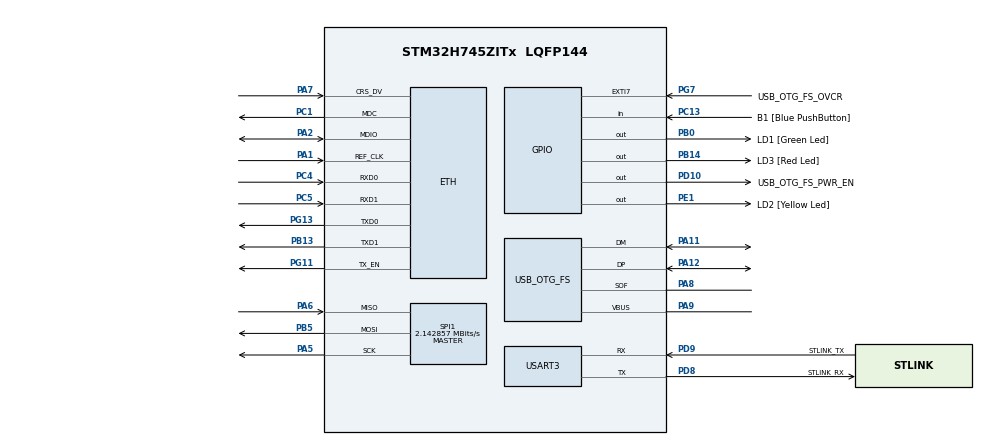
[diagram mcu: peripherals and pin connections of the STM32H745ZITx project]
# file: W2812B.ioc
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CORTEX_M7.CPU_DCache=Disabled
CORTEX_M7.CPU_ICache=Enabled
CortexM4.IPs=FATFS_M4\:I,FREERTOS_M4\:I,IWDG2\:I,RCC,WWDG2\:I,DMA,BDMA,MDMA,NVIC2\:I,USART3,ETH,DEBUG,USB_DEVICE_M4\:I,USB_HOST_M4\:I,PDM2PCM_M4\:I,PWR,RESMGR_UTILITY,SYS_M4\:I,CORTEX_M4\:I,OPENAMP_M4\:I,VREFBUF
CortexM7.IPs=FATFS_M7\:I,FREERTOS_M7\:I,IWDG1\:I,RCC\:I,WWDG1\:I,DMA\:I,BDMA\:I,MDMA\:I,NVIC1\:I,SYS\:I,USART3\:I,USB_OTG_FS\:I,ETH\:I,CORTEX_M7\:I,DEBUG\:I,USB_DEVICE_M7\:I,USB_HOST_M7\:I,PDM2PCM_M7\:I,PWR\:I,RESMGR_UTILITY\:I,OPENAMP_M7\:I,VREFBUF\:I,SPI1\:I
Dma.Request0=SPI1_TX
Dma.SPI1_TX.0.Direction=DMA_MEMORY_TO_PERIPH
Dma.SPI1_TX.0.EventEnable=DISABLE
Dma.SPI1_TX.0.FIFOMode=DMA_FIFOMODE_DISABLE
Dma.SPI1_TX.0.Instance=DMA2_Stream0
Dma.SPI1_TX.0.MemDataAlignment=DMA_MDATAALIGN_BYTE
Dma.SPI1_TX.0.MemInc=DMA_MINC_ENABLE
Dma.SPI1_TX.0.Mode=DMA_CIRCULAR
Dma.SPI1_TX.0.PeriphDataAlignment=DMA_PDATAALIGN_BYTE
Dma.SPI1_TX.0.PeriphInc=DMA_PINC_DISABLE
Dma.SPI1_TX.0.Polarity=HAL_DMAMUX_REQ_GEN_RISING
Dma.SPI1_TX.0.Priority=DMA_PRIORITY_LOW
Dma.SPI1_TX.0.RequestNumber=1
Dma.SPI1_TX.0.SignalID=NONE
Dma.SPI1_TX.0.SyncEnable=DISABLE
Dma.SPI1_TX.0.SyncPolarity=HAL_DMAMUX_SYNC_NO_EVENT
Dma.SPI1_TX.0.SyncRequestNumber=1
Dma.SPI1_TX.0.SyncSignalID=NONE
ETH.MediaInterface=HAL_ETH_RMII_MODE
Mcu.Family=STM32H7
Mcu.Name=STM32H745ZITx
Mcu.Package=LQFP144
NVIC1.DMA2_Stream0_IRQn=true\:0\:0\:false\:false\:true\:false\:true
NVIC1.PriorityGroup=NVIC_PRIORITYGROUP_4
NVIC1.SPI1_IRQn=true\:0\:0\:false\:false\:true\:false\:true
NVIC2.PriorityGroup=NVIC_PRIORITYGROUP_4
PA1.Mode=RMII
PA1.PinAttribute=CortexM7
PA1.Signal=ETH_REF_CLK
PA11.Mode=Device_Only
PA11.PinAttribute=CortexM7
PA11.Signal=USB_OTG_FS_DM
PA12.Mode=Device_Only
PA12.PinAttribute=CortexM7
PA12.Signal=USB_OTG_FS_DP
PA2.Mode=RMII
PA2.PinAttribute=CortexM7
PA2.Signal=ETH_MDIO
PA5.GPIO_Speed=GPIO_SPEED_FREQ_LOW
PA5.Mode=Full_Duplex_Master
PA5.PinAttribute=CortexM7
PA5.Signal=SPI1_SCK
PA6.Mode=Full_Duplex_Master
PA6.PinAttribute=CortexM7
PA6.Signal=SPI1_MISO
PA7.Mode=RMII
PA7.PinAttribute=CortexM7
PA7.Signal=ETH_CRS_DV
PA8.Mode=Activate_SOF_FS
PA8.PinAttribute=CortexM7
PA8.Signal=USB_OTG_FS_SOF
PA9.Mode=Activate_VBUS
PA9.PinAttribute=CortexM7
PA9.Signal=USB_OTG_FS_VBUS
PB0.GPIO_Label=LD1 [Green Led]
PB0.PinAttribute=Free
PB0.Signal=GPIO_Output
PB13.Mode=RMII
PB13.PinAttribute=CortexM7
PB13.Signal=ETH_TXD1
PB14.GPIO_Label=LD3 [Red Led]
PB14.PinAttribute=Free
PB14.Signal=GPIO_Output
PB5.GPIO_Speed=GPIO_SPEED_FREQ_VERY_HIGH
PB5.Mode=Full_Duplex_Master
PB5.PinAttribute=CortexM7
PB5.Signal=SPI1_MOSI
PC1.Mode=RMII
PC1.PinAttribute=CortexM7
PC1.Signal=ETH_MDC
PC13.GPIO_Label=B1 [Blue PushButton]
PC13.PinAttribute=Free
PC13.Signal=GPIO_Input
PC14-OSC32_IN\ (OSC32_IN).Mode=LSE-External-Oscillator
PC14-OSC32_IN\ (OSC32_IN).PinAttribute=CortexM7
PC14-OSC32_IN\ (OSC32_IN).Signal=RCC_OSC32_IN
PC15-OSC32_OUT\ (OSC32_OUT).Mode=LSE-External-Oscillator
PC15-OSC32_OUT\ (OSC32_OUT).PinAttribute=CortexM7
PC15-OSC32_OUT\ (OSC32_OUT).Signal=RCC_OSC32_OUT
PC4.Mode=RMII
PC4.PinAttribute=CortexM7
PC4.Signal=ETH_RXD0
PC5.Mode=RMII
PC5.PinAttribute=CortexM7
PC5.Signal=ETH_RXD1
PD10.GPIO_Label=USB_OTG_FS_PWR_EN
PD10.PinAttribute=Free
PD10.Signal=GPIO_Output
PD8.GPIO_Label=STLINK_RX
PD8.Mode=Asynchronous
PD8.PinAttribute=CortexM7
PD8.Signal=USART3_TX
PD9.GPIO_Label=STLINK_TX
PD9.Mode=Asynchronous
PD9.PinAttribute=CortexM7
PD9.Signal=USART3_RX
PE1.GPIO_Label=LD2 [Yellow Led]
PE1.PinAttribute=Free
PE1.Signal=GPIO_Output
PG11.Mode=RMII
PG11.PinAttribute=CortexM7
PG11.Signal=ETH_TX_EN
PG13.Mode=RMII
PG13.PinAttribute=CortexM7
PG13.Signal=ETH_TXD0
PG7.GPIO_Label=USB_OTG_FS_OVCR
PG7.PinAttribute=Free
PG7.Signal=GPXTI7
PH0-OSC_IN\ (PH0).Mode=HSE-External-Clock-Source
PH0-OSC_IN\ (PH0).PinAttribute=CortexM7
PH0-OSC_IN\ (PH0).Signal=RCC_OSC_IN
PH1-OSC_OUT\ (PH1).PinAttribute=CortexM7
PH1-OSC_OUT\ (PH1).Signal=RCC_OSC_OUT
ProjectManager.HeapSize=M4-0x200,M7-0x200
ProjectManager.StackSize=M4-0x400,M7-0x400
ProjectManager.TargetToolchain=STM32CubeIDE
RCC.ADCFreq_Value=16125000
RCC.APB1Freq_Value=120000000
RCC.APB2Freq_Value=120000000
RCC.APB3Freq_Value=120000000
RCC.APB4Freq_Value=120000000
RCC.CortexFreq_Value=480000000
RCC.D1PPRE=RCC_APB3_DIV2
RCC.D2PPRE1=RCC_APB1_DIV2
RCC.D2PPRE2=RCC_APB2_DIV2
RCC.D3PPRE=RCC_APB4_DIV2
RCC.DIVM1=1
RCC.DIVM3=1
RCC.DIVN1=120
RCC.DIVN3=24
RCC.DIVQ1=7
RCC.DIVQ3=4
RCC.HCLKFreq_Value=240000000
RCC.HPRE=RCC_HCLK_DIV2
RCC.HSE_VALUE=8000000
RCC.PLL2FRACN=0
RCC.PLL3FRACN=0
RCC.PLLFRACN=0
RCC.SYSCLKFreq_VALUE=480000000
RCC.SYSCLKSource=RCC_SYSCLKSOURCE_PLLCLK
RCC.SupplySource=PWR_DIRECT_SMPS_SUPPLY
RCC.USBCLockSelection=RCC_USBCLKSOURCE_PLL3
RCC.USBFreq_Value=48000000
SPI1.BaudRatePrescaler=SPI_BAUDRATEPRESCALER_64
SPI1.CalculateBaudRate=2.142857 MBits/s
SPI1.DataSize=SPI_DATASIZE_8BIT
SPI1.Direction=SPI_DIRECTION_2LINES
SPI1.MasterKeepIOState=SPI_MASTER_KEEP_IO_STATE_ENABLE
SPI1.Mode=SPI_MODE_MASTER
SPI1.NSSPMode=SPI_NSS_PULSE_DISABLE
SPI1.VirtualType=VM_MASTER
USART3.VirtualMode-Asynchronous=VM_ASYNC
USB_OTG_FS.VirtualMode=Device_Only
VP_SYS_M4_VS_Systick.Mode=SysTick
board=NUCLEO-H745ZI-Q

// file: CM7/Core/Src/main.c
/* USER CODE BEGIN Header */
/**
  ******************************************************************************
  * @file           : main.c
  * @brief          : Main program body
  ******************************************************************************
  * @attention
  *
  * <h2><center>&copy; Copyright (c) 2021 STMicroelectronics.
  * All rights reserved.</center></h2>
  *
  * This software component is licensed by ST under BSD 3-Clause license,
  * the "License"; You may not use this file except in compliance with the
  * License. You may obtain a copy of the License at:
  *                        opensource.org/licenses/BSD-3-Clause
  *
  ******************************************************************************
  */
/* USER CODE END Header */
#include "main.h"
#include "string.h"

/* USER CODE BEGIN Includes */
#include "W2812BSPI.h"
/* USER CODE END Includes */

/* USER CODE BEGIN PD */

#ifndef HSEM_ID_0
#define HSEM_ID_0 (0U) /* HW semaphore 0*/
#endif
/* USER CODE END PD */

#if defined ( __ICCARM__ ) /*!< IAR Compiler */

#pragma location=0x30040000
ETH_DMADescTypeDef  DMARxDscrTab[ETH_RX_DESC_CNT]; /* Ethernet Rx DMA Descriptors */
#pragma location=0x30040060
ETH_DMADescTypeDef  DMATxDscrTab[ETH_TX_DESC_CNT]; /* Ethernet Tx DMA Descriptors */
#pragma location=0x30040200
uint8_t Rx_Buff[ETH_RX_DESC_CNT][ETH_MAX_PACKET_SIZE]; /* Ethernet Receive Buffers */

#elif defined ( __CC_ARM )  /* MDK ARM Compiler */

__attribute__((at(0x30040000))) ETH_DMADescTypeDef  DMARxDscrTab[ETH_RX_DESC_CNT]; /* Ethernet Rx DMA Descriptors */
__attribute__((at(0x30040060))) ETH_DMADescTypeDef  DMATxDscrTab[ETH_TX_DESC_CNT]; /* Ethernet Tx DMA Descriptors */
__attribute__((at(0x30040200))) uint8_t Rx_Buff[ETH_RX_DESC_CNT][ETH_MAX_PACKET_SIZE]; /* Ethernet Receive Buffer */

#elif defined ( __GNUC__ ) /* GNU Compiler */

ETH_DMADescTypeDef DMARxDscrTab[ETH_RX_DESC_CNT] __attribute__((section(".RxDecripSection"))); /* Ethernet Rx DMA Descriptors */
ETH_DMADescTypeDef DMATxDscrTab[ETH_TX_DESC_CNT] __attribute__((section(".TxDecripSection")));   /* Ethernet Tx DMA Descriptors */
uint8_t Rx_Buff[ETH_RX_DESC_CNT][ETH_MAX_PACKET_SIZE] __attribute__((section(".RxArraySection"))); /* Ethernet Receive Buffers */

#endif

ETH_TxPacketConfig TxConfig;

ETH_HandleTypeDef heth;

SPI_HandleTypeDef hspi1;
DMA_HandleTypeDef hdma_spi1_tx;

UART_HandleTypeDef huart3;

PCD_HandleTypeDef hpcd_USB_OTG_FS;

/* USER CODE BEGIN PV */
W2812BStructure LED[8]={0};

/* USER CODE END PV */

void SystemClock_Config(void);
static void MX_GPIO_Init(void);
static void MX_ETH_Init(void);
static void MX_USART3_UART_Init(void);
static void MX_USB_OTG_FS_PCD_Init(void);
static void MX_DMA_Init(void);
static void MX_SPI1_Init(void);

int main(void)
{
/* USER CODE BEGIN Boot_Mode_Sequence_0 */
  int32_t timeout;
/* USER CODE END Boot_Mode_Sequence_0 */

  /* Enable I-Cache---------------------------------------------------------*/
  SCB_EnableICache();

/* USER CODE BEGIN Boot_Mode_Sequence_1 */
  /* Wait until CPU2 boots and enters in stop mode or timeout*/
  timeout = 0xFFFF;
  while((__HAL_RCC_GET_FLAG(RCC_FLAG_D2CKRDY) != RESET) && (timeout-- > 0));
  if ( timeout < 0 )
  {
  Error_Handler();
  }
/* USER CODE END Boot_Mode_Sequence_1 */
  /* MCU Configuration--------------------------------------------------------*/

  /* Reset of all peripherals, Initializes the Flash interface and the Systick. */
  HAL_Init();

  /* Configure the system clock */
  SystemClock_Config();
/* USER CODE BEGIN Boot_Mode_Sequence_2 */
/* When system initialization is finished, Cortex-M7 will release Cortex-M4 by means of
HSEM notification */
/*HW semaphore Clock enable*/
__HAL_RCC_HSEM_CLK_ENABLE();
/*Take HSEM */
HAL_HSEM_FastTake(HSEM_ID_0);
/*Release HSEM in order to notify the CPU2(CM4)*/
HAL_HSEM_Release(HSEM_ID_0,0);
/* wait until CPU2 wakes up from stop mode */
timeout = 0xFFFF;
while((__HAL_RCC_GET_FLAG(RCC_FLAG_D2CKRDY) == RESET) && (timeout-- > 0));
if ( timeout < 0 )
{
Error_Handler();
}
/* USER CODE END Boot_Mode_Sequence_2 */

  /* Initialize all configured peripherals */
  MX_GPIO_Init();
  MX_ETH_Init();
  MX_USART3_UART_Init();
  MX_USB_OTG_FS_PCD_Init();
  MX_DMA_Init();
  MX_SPI1_Init();
  /* USER CODE BEGIN 2 */
  GPIOB->OTYPER = GPIOB->OTYPER | GPIO_PIN_5; // set output  open drain
  W2812B_Init(&hspi1);
  /* USER CODE END 2 */

  /* Infinite loop */
  /* USER CODE BEGIN WHILE */
  while (1)
  {
	  static int h =0;
    /* USER CODE END WHILE */

    /* USER CODE BEGIN 3 */

		HAL_Delay(1);
		for (int i = 0; i < 8; i++) {

			HToRGB((h + 192*i) % 1536, &LED[i]);
		}

		h++;
		h%=1536;
	  W2812B_UpdateData(LED);

  }
  /* USER CODE END 3 */
}

void SystemClock_Config(void)
{
  RCC_OscInitTypeDef RCC_OscInitStruct = {0};
  RCC_ClkInitTypeDef RCC_ClkInitStruct = {0};

  /** Supply configuration update enable
  */
  HAL_PWREx_ConfigSupply(PWR_DIRECT_SMPS_SUPPLY);
  /** Configure the main internal regulator output voltage
  */
  __HAL_PWR_VOLTAGESCALING_CONFIG(PWR_REGULATOR_VOLTAGE_SCALE0);

  while(!__HAL_PWR_GET_FLAG(PWR_FLAG_VOSRDY)) {}
  /** Macro to configure the PLL clock source
  */
  __HAL_RCC_PLL_PLLSOURCE_CONFIG(RCC_PLLSOURCE_HSE);
  /** Initializes the RCC Oscillators according to the specified parameters
  * in the RCC_OscInitTypeDef structure.
  */
  RCC_OscInitStruct.OscillatorType = RCC_OSCILLATORTYPE_HSE;
  RCC_OscInitStruct.HSEState = RCC_HSE_BYPASS;
  RCC_OscInitStruct.PLL.PLLState = RCC_PLL_ON;
  RCC_OscInitStruct.PLL.PLLSource = RCC_PLLSOURCE_HSE;
  RCC_OscInitStruct.PLL.PLLM = 1;
  RCC_OscInitStruct.PLL.PLLN = 120;
  RCC_OscInitStruct.PLL.PLLP = 2;
  RCC_OscInitStruct.PLL.PLLQ = 7;
  RCC_OscInitStruct.PLL.PLLR = 2;
  RCC_OscInitStruct.PLL.PLLRGE = RCC_PLL1VCIRANGE_3;
  RCC_OscInitStruct.PLL.PLLVCOSEL = RCC_PLL1VCOWIDE;
  RCC_OscInitStruct.PLL.PLLFRACN = 0;
  if (HAL_RCC_OscConfig(&RCC_OscInitStruct) != HAL_OK)
  {
    Error_Handler();
  }
  /** Initializes the CPU, AHB and APB buses clocks
  */
  RCC_ClkInitStruct.ClockType = RCC_CLOCKTYPE_HCLK|RCC_CLOCKTYPE_SYSCLK
                              |RCC_CLOCKTYPE_PCLK1|RCC_CLOCKTYPE_PCLK2
                              |RCC_CLOCKTYPE_D3PCLK1|RCC_CLOCKTYPE_D1PCLK1;
  RCC_ClkInitStruct.SYSCLKSource = RCC_SYSCLKSOURCE_PLLCLK;
  RCC_ClkInitStruct.SYSCLKDivider = RCC_SYSCLK_DIV1;
  RCC_ClkInitStruct.AHBCLKDivider = RCC_HCLK_DIV2;
  RCC_ClkInitStruct.APB3CLKDivider = RCC_APB3_DIV2;
  RCC_ClkInitStruct.APB1CLKDivider = RCC_APB1_DIV2;
  RCC_ClkInitStruct.APB2CLKDivider = RCC_APB2_DIV2;
  RCC_ClkInitStruct.APB4CLKDivider = RCC_APB4_DIV2;

  if (HAL_RCC_ClockConfig(&RCC_ClkInitStruct, FLASH_LATENCY_4) != HAL_OK)
  {
    Error_Handler();
  }
}

static void MX_ETH_Init(void)
{

   static uint8_t MACAddr[6];

  heth.Instance = ETH;
  MACAddr[0] = 0x00;
  MACAddr[1] = 0x80;
  MACAddr[2] = 0xE1;
  MACAddr[3] = 0x00;
  MACAddr[4] = 0x00;
  MACAddr[5] = 0x00;
  heth.Init.MACAddr = &MACAddr[0];
  heth.Init.MediaInterface = HAL_ETH_RMII_MODE;
  heth.Init.TxDesc = DMATxDscrTab;
  heth.Init.RxDesc = DMARxDscrTab;
  heth.Init.RxBuffLen = 1524;

  if (HAL_ETH_Init(&heth) != HAL_OK)
  {
    Error_Handler();
  }

  memset(&TxConfig, 0 , sizeof(ETH_TxPacketConfig));
  TxConfig.Attributes = ETH_TX_PACKETS_FEATURES_CSUM | ETH_TX_PACKETS_FEATURES_CRCPAD;
  TxConfig.ChecksumCtrl = ETH_CHECKSUM_IPHDR_PAYLOAD_INSERT_PHDR_CALC;
  TxConfig.CRCPadCtrl = ETH_CRC_PAD_INSERT;

}

static void MX_SPI1_Init(void)
{

  /* SPI1 parameter configuration*/
  hspi1.Instance = SPI1;
  hspi1.Init.Mode = SPI_MODE_MASTER;
  hspi1.Init.Direction = SPI_DIRECTION_2LINES;
  hspi1.Init.DataSize = SPI_DATASIZE_8BIT;
  hspi1.Init.CLKPolarity = SPI_POLARITY_LOW;
  hspi1.Init.CLKPhase = SPI_PHASE_1EDGE;
  hspi1.Init.NSS = SPI_NSS_SOFT;
  hspi1.Init.BaudRatePrescaler = SPI_BAUDRATEPRESCALER_64;
  hspi1.Init.FirstBit = SPI_FIRSTBIT_MSB;
  hspi1.Init.TIMode = SPI_TIMODE_DISABLE;
  hspi1.Init.CRCCalculation = SPI_CRCCALCULATION_DISABLE;
  hspi1.Init.CRCPolynomial = 0x0;
  hspi1.Init.NSSPMode = SPI_NSS_PULSE_DISABLE;
  hspi1.Init.NSSPolarity = SPI_NSS_POLARITY_LOW;
  hspi1.Init.FifoThreshold = SPI_FIFO_THRESHOLD_01DATA;
  hspi1.Init.TxCRCInitializationPattern = SPI_CRC_INITIALIZATION_ALL_ZERO_PATTERN;
  hspi1.Init.RxCRCInitializationPattern = SPI_CRC_INITIALIZATION_ALL_ZERO_PATTERN;
  hspi1.Init.MasterSSIdleness = SPI_MASTER_SS_IDLENESS_00CYCLE;
  hspi1.Init.MasterInterDataIdleness = SPI_MASTER_INTERDATA_IDLENESS_00CYCLE;
  hspi1.Init.MasterReceiverAutoSusp = SPI_MASTER_RX_AUTOSUSP_DISABLE;
  hspi1.Init.MasterKeepIOState = SPI_MASTER_KEEP_IO_STATE_ENABLE;
  hspi1.Init.IOSwap = SPI_IO_SWAP_DISABLE;
  if (HAL_SPI_Init(&hspi1) != HAL_OK)
  {
    Error_Handler();
  }

}

static void MX_USART3_UART_Init(void)
{

  huart3.Instance = USART3;
  huart3.Init.BaudRate = 115200;
  huart3.Init.WordLength = UART_WORDLENGTH_8B;
  huart3.Init.StopBits = UART_STOPBITS_1;
  huart3.Init.Parity = UART_PARITY_NONE;
  huart3.Init.Mode = UART_MODE_TX_RX;
  huart3.Init.HwFlowCtl = UART_HWCONTROL_NONE;
  huart3.Init.OverSampling = UART_OVERSAMPLING_16;
  huart3.Init.OneBitSampling = UART_ONE_BIT_SAMPLE_DISABLE;
  huart3.Init.ClockPrescaler = UART_PRESCALER_DIV1;
  huart3.AdvancedInit.AdvFeatureInit = UART_ADVFEATURE_NO_INIT;
  if (HAL_UART_Init(&huart3) != HAL_OK)
  {
    Error_Handler();
  }
  if (HAL_UARTEx_SetTxFifoThreshold(&huart3, UART_TXFIFO_THRESHOLD_1_8) != HAL_OK)
  {
    Error_Handler();
  }
  if (HAL_UARTEx_SetRxFifoThreshold(&huart3, UART_RXFIFO_THRESHOLD_1_8) != HAL_OK)
  {
    Error_Handler();
  }
  if (HAL_UARTEx_DisableFifoMode(&huart3) != HAL_OK)
  {
    Error_Handler();
  }

}

static void MX_USB_OTG_FS_PCD_Init(void)
{

  hpcd_USB_OTG_FS.Instance = USB_OTG_FS;
  hpcd_USB_OTG_FS.Init.dev_endpoints = 9;
  hpcd_USB_OTG_FS.Init.speed = PCD_SPEED_FULL;
  hpcd_USB_OTG_FS.Init.dma_enable = DISABLE;
  hpcd_USB_OTG_FS.Init.phy_itface = PCD_PHY_EMBEDDED;
  hpcd_USB_OTG_FS.Init.Sof_enable = DISABLE;
  hpcd_USB_OTG_FS.Init.low_power_enable = DISABLE;
  hpcd_USB_OTG_FS.Init.lpm_enable = DISABLE;
  hpcd_USB_OTG_FS.Init.battery_charging_enable = ENABLE;
  hpcd_USB_OTG_FS.Init.vbus_sensing_enable = ENABLE;
  hpcd_USB_OTG_FS.Init.use_dedicated_ep1 = DISABLE;
  if (HAL_PCD_Init(&hpcd_USB_OTG_FS) != HAL_OK)
  {
    Error_Handler();
  }

}

static void MX_DMA_Init(void)
{

  /* DMA controller clock enable */
  __HAL_RCC_DMA2_CLK_ENABLE();

  /* DMA interrupt init */
  /* DMA2_Stream0_IRQn interrupt configuration */
  HAL_NVIC_SetPriority(DMA2_Stream0_IRQn, 0, 0);
  HAL_NVIC_EnableIRQ(DMA2_Stream0_IRQn);

}

static void MX_GPIO_Init(void)
{

  /* GPIO Ports Clock Enable */
  __HAL_RCC_GPIOC_CLK_ENABLE();
  __HAL_RCC_GPIOH_CLK_ENABLE();
  __HAL_RCC_GPIOA_CLK_ENABLE();
  __HAL_RCC_GPIOB_CLK_ENABLE();
  __HAL_RCC_GPIOD_CLK_ENABLE();
  __HAL_RCC_GPIOG_CLK_ENABLE();

}

void Error_Handler(void)
{
  __disable_irq();
  while (1)
  {
  }
}

/************************ (C) COPYRIGHT STMicroelectronics *****END OF FILE****/
